# PIC32CK2051SG00100 device description
Architecture: CORTEX-M33; Family: PIC32CK; Series: PIC32CKSG00
Registers are 32-bit, read-write, reset 0x0 unless marked. A register's access mark holds for its fields unless they carry their own. Offsets are from the block's base; [hi:lo] are bit positions; {n}, {i} and the like mark numbered series; 'fields as' and 'values as' point back to an identical list.

## FUSES_BOOTCFG1 — Defines FUSE parameters
Instances: FUSES_BOOTCFG1 0x0A002000, FUSES_BOOTCFG2 0x0A00A000
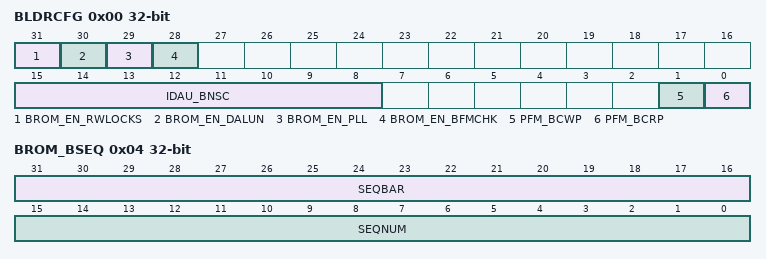
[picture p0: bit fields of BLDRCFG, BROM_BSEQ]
0x00 BLDRCFG reset not defined — Bootloader Configuration
  [31] BROM_EN_RWLOCKS — Enable Read/Write Locks
  [30] BROM_EN_DALUN — Enable DAL Unlock
  [29] BROM_EN_PLL — Enable PLL (Settings in PLL0_<REGS> are used)
  [28] BROM_EN_BFMCHK — Enable BFM CRC Check
    0=NONE (No verification); 1=CRC32 (Verify using crc32)
  [15:8] IDAU_BNSC — Boot Non-Secure Callable Size
  [1] PFM_BCWP — Boot Configration Page Write Protect
  [0] PFM_BCRP — Boot Configration Page Read Protect
0x04 BROM_BSEQ reset not defined — Boot Configuraiton Page Sequence Number
  [31:16] SEQBAR — Sequence Number Bar (Negeated)
  [15:0] SEQNUM — Sequence Number
0x08 BFM_CHK_TABLEPTR reset not defined — BFM CRC Table Pointer
{0x20+4i} KEYVAL_TZ1_CE_NS[{i}] (i=0..3) reset not defined — Chip Erase Key for TZ1_NS
{0x30+4i} CELOCK_TZ1_CE_NS[{i}] (i=0..3) reset not defined — Chip Erase Lock for TZ1_NS
{0x40+4i} KEYVAL_TZ1_CE_S[{i}] (i=0..3) reset not defined — Chip Erase Key for TZ1_S
{0x50+4i} CELOCK_TZ1_CE_S[{i}] (i=0..3) reset not defined — Chip Erase Lock for TZ1_S
{0x60+4i} KEYVAL_TZ1_CE_ALL[{i}] (i=0..3) reset not defined — Chip Erase Key for TZ1_ALL
{0x70+4i} CELOCK_TZ1_CE_ALL[{i}] (i=0..3) reset not defined — Chip Erase Lock for TZ1_ALL
{0x80+4i} KEYVAL_TZ0_CE_ALL[{i}] (i=0..3) reset not defined — Chip Erase Key for TZ0_ALL
{0x90+4i} CELOCK_TZ0_CE_ALL[{i}] (i=0..3) reset not defined — Chip Erase Lock for TZ0_ALL
{0xA0+4i} KEYVAL_CRCCMD[{i}] (i=0..3) reset not defined — CRC Access Key
{0xB0+4i} KEYCONFIG_CRCCMD[{i}] (i=0..3) reset not defined — CRC Access Key Configuration
{0xC0+4i} KEYVAL_HOSTDALELEV[{i}] (i=0..3) reset not defined — Host Authenticated DAL Elevation Key
{0xD0+4i} KEYCONFIG_HOSTDALELEV[{i}] (i=0..3) reset not defined — Host Authenticated DAL Elevation Key Configuration
0xE0 ROM_CTRLA reset not defined — ROM CTRLA Settings (BROM_PLLEN must be set)
0xE4 FCR_CTRLA reset not defined — FCR CTRLA Settings (BROM_PLLEN must be set)
0xE8 RPMU_VREGCTRL reset not defined — RPMU VREGCTRL Settings (BROM_PLLEN must be set)
0xEC PLL0_CTRL reset not defined — PLL0 CTRL Settings (BROM_PLLEN must be set)
0xF0 PLL0_FBDIV reset not defined — PLL0 FBDIV Settings (BROM_PLLEN must be set)
0xF4 PLL0_REFDIV reset not defined — PLL0 REFDIV Settings (BROM_PLLEN must be set)
0xF8 PLL0_POSTDIVA reset not defined — PLL0 POSTDIVA Settings (BROM_PLLEN must be set)
0xFC MCLK_CLKDIV1 reset not defined — MCLK CLKDIV1 Settings (BROM_PLLEN must be set)
0x100 GCLK_GENCTRL0 reset not defined — GCLK GENCTRL0 Settings (BROM_PLLEN must be set)
{0x110+4i} BROM_BOOTCFGCRC[{i}] (i=0..3) reset not defined — Boot Configuraiton Page CRC
0x120 BROM_PAGEEND reset not defined — Page End Marker for Verified Data

## FUSES_DALCFG — Defines FUSE parameters
Instances: FUSES_DALCFG 0x0A004000
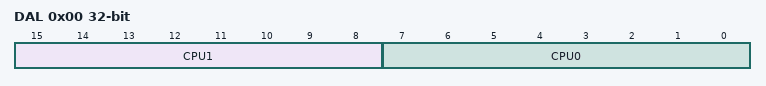
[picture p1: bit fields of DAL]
0x00 DAL — Debug Access Level
  [15:8] CPU1 — HSM DAL Elevation Value
    129=DAL0 (FCW_DAL0_VALUE); 153=DAL1 (FCW_DAL1_VALUE); 219=DAL2 (FCW_DAL2_VALUE)
  [7:0] CPU0 — Host DAL Elevation Value
    values as CPU1

## FUSES_CALOTP — Defines FUSE parameters
Instances: FUSES_CALOTP 0x0A007000
0x180 FCCFG64 ro reset not defined — PTC Calibration
  [15:0] PTCFG0
0x184 FCCFG65 ro reset not defined — ADC Calibration
  [31:0] ADCFG0
0x188 FCCFG66 ro reset not defined — Comparator Calibration
  [7:0] ACPAIR_SEL
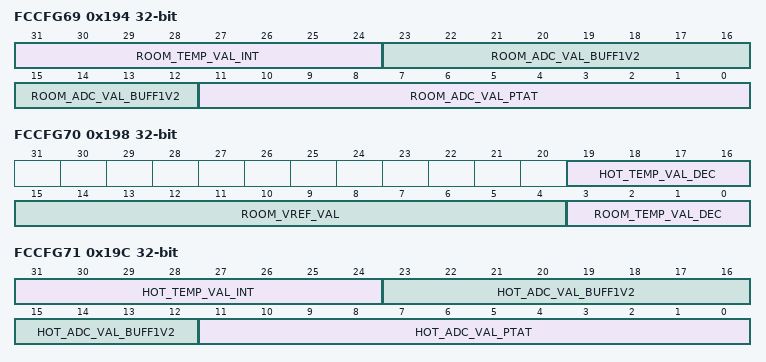
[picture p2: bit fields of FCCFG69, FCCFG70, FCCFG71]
0x194 FCCFG69 ro reset not defined — Temperature calibration values 0
  [31:24] ROOM_TEMP_VAL_INT, [23:12] ROOM_ADC_VAL_BUFF1V2, [11:0] ROOM_ADC_VAL_PTAT
0x198 FCCFG70 ro reset not defined — Temperature calibration values 1
  [19:16] HOT_TEMP_VAL_DEC, [15:4] ROOM_VREF_VAL, [3:0] ROOM_TEMP_VAL_DEC
0x19C FCCFG71 ro reset not defined — Temperature calibration values 2
  [31:24] HOT_TEMP_VAL_INT, [23:12] HOT_ADC_VAL_BUFF1V2, [11:0] HOT_ADC_VAL_PTAT
0x1A0 FCCFG72 ro reset not defined — MAC ID (31 through 0)
  [31:0] FMAC_31_0
0x1A4 FCCFG73 ro reset not defined — MAC ID (47 through 32)
  [15:0] FMAC_47_32

## Notices in the file
Copyright (c) 2021 Microchip Technology Inc.
SPDX-License-Identifier: Apache-2.0
Licensed under the Apache License, Version 2.0 (the "License");
you may not use this file except in compliance with the License.
You may obtain a copy of the License at
http://www.apache.org/licenses/LICENSE-2.0
Unless required by applicable law or agreed to in writing, software
distributed under the License is distributed on an "AS IS" BASIS,
WITHOUT WARRANTIES OR CONDITIONS OF ANY KIND, either express or implied.
See the License for the specific language governing permissions and
limitations under the License.
